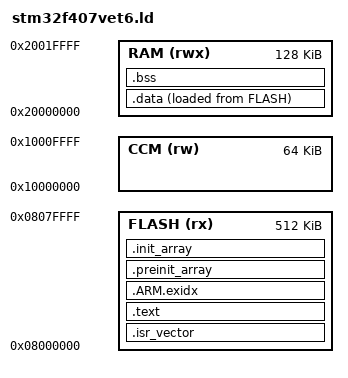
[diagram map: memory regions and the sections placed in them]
/*
 * Provisional single-image layout for STM32F407VET6. The board generator
 * replaces this with the Flash layout of ADR-0020 (S0 stub, firmware at S4).
 */
ENTRY(Reset_Handler)

MEMORY
{
    FLASH (rx)  : ORIGIN = 0x08000000, LENGTH = 512K
    RAM   (rwx) : ORIGIN = 0x20000000, LENGTH = 128K
    CCM   (rw)  : ORIGIN = 0x10000000, LENGTH = 64K
}

_estack = ORIGIN(RAM) + LENGTH(RAM);

SECTIONS
{
    .isr_vector :
    {
        . = ALIGN(4);
        KEEP(*(.isr_vector))
        . = ALIGN(4);
    } > FLASH

    .text :
    {
        . = ALIGN(4);
        *(.text .text.*)
        *(.rodata .rodata.*)
        KEEP(*(.init))
        KEEP(*(.fini))
        . = ALIGN(4);
    } > FLASH

    .ARM.exidx :
    {
        *(.ARM.exidx* .gnu.linkonce.armexidx.*)
    } > FLASH

    .preinit_array :
    {
        PROVIDE_HIDDEN(__preinit_array_start = .);
        KEEP(*(.preinit_array*))
        PROVIDE_HIDDEN(__preinit_array_end = .);
    } > FLASH

    .init_array :
    {
        PROVIDE_HIDDEN(__init_array_start = .);
        KEEP(*(SORT(.init_array.*)))
        KEEP(*(.init_array*))
        PROVIDE_HIDDEN(__init_array_end = .);
    } > FLASH

    _sidata = LOADADDR(.data);

    .data :
    {
        . = ALIGN(4);
        _sdata = .;
        *(.data .data.*)
        . = ALIGN(4);
        _edata = .;
    } > RAM AT > FLASH

    .bss (NOLOAD) :
    {
        . = ALIGN(4);
        _sbss = .;
        *(.bss .bss.*)
        *(COMMON)
        . = ALIGN(4);
        _ebss = .;
    } > RAM
}
